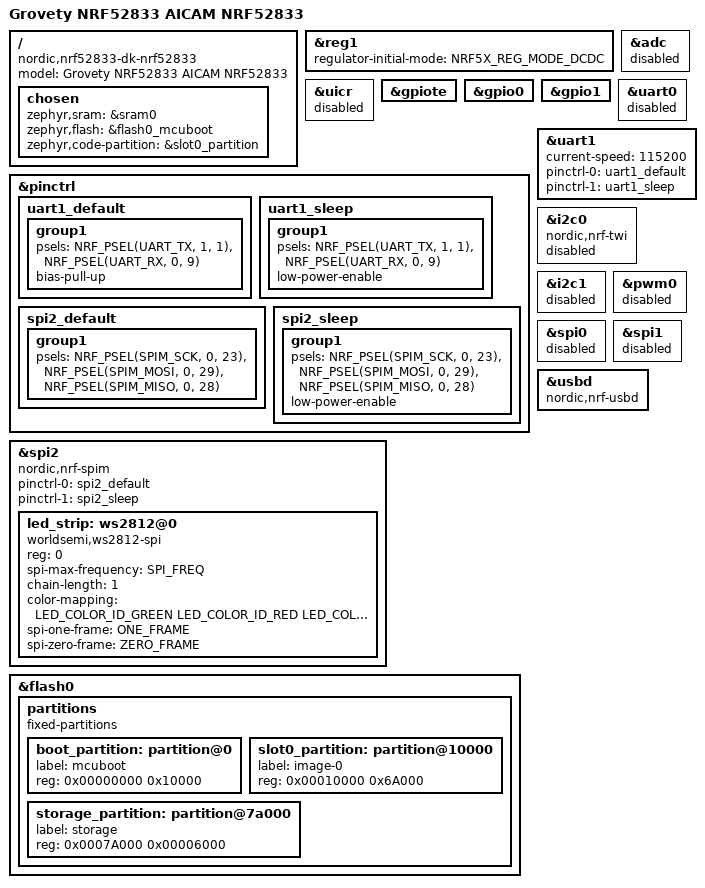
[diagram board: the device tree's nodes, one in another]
/*
 * Copyright (c) 2025 Grovety Inc
 *
 * SPDX-License-Identifier: Apache-2.0
 */

/dts-v1/;
#include <nordic/nrf52833_qiaa.dtsi>
#include <zephyr/dt-bindings/input/input-event-codes.h>

/ {
	model = "Grovety NRF52833 AICAM NRF52833";
	compatible = "nordic,nrf52833-dk-nrf52833";

	chosen {
		zephyr,sram = &sram0;
		zephyr,flash = &flash0_mcuboot;
		zephyr,code-partition = &slot0_partition;
	};
};

&reg1 {
	regulator-initial-mode = <NRF5X_REG_MODE_DCDC>;
};

&adc {
	status = "disabled";
};

&uicr {
	status = "disabled";
};

&gpiote {
	status = "okay";
};

&gpio0 {
	status = "okay";
};

&gpio1 {
	status = "okay";
};

&uart0 {
	status = "disabled";
};

&pinctrl {
	uart1_default: uart1_default {
		group1 {
			psels = <NRF_PSEL(UART_TX, 1, 1)>,
			        <NRF_PSEL(UART_RX, 0, 9)>;
		bias-pull-up;
	  };
	};
	uart1_sleep: uart1_sleep {
	  	group1 {
			psels = <NRF_PSEL(UART_TX, 1, 1)>,
			        <NRF_PSEL(UART_RX, 0, 9)>;
		low-power-enable;
	  	};
	};
};

&uart1 {
	status = "okay";
	current-speed = <115200>;
	pinctrl-0 = <&uart1_default>;
	pinctrl-1 = <&uart1_sleep>;
	pinctrl-names = "default", "sleep";
};

&i2c0 {
	compatible = "nordic,nrf-twi";
	status = "disabled";
};

&i2c1 {
	status = "disabled";
};

&pwm0 {
	status = "disabled";
};

&spi0 {
	status = "disabled";
};

&spi1 {
	status = "disabled";
};

&spi2 {
	status = "disabled";
};

/*flash0_default: &flash0 {
	partitions {
		compatible = "fixed-partitions";
		#address-cells = <1>;
		#size-cells = <1>;

		boot_partition: partition@0 {
			label = "mcuboot";
			reg = <0x00000000 0xC000>;
		};
		slot0_partition: partition@c000 {
			label = "image-0";
			reg = <0x0000C000 0x37000>;
		};
		slot1_partition: partition@43000 {
			label = "image-1";
			reg = <0x00043000 0x37000>;
		};
		storage_partition: partition@7a000 {
			label = "storage";
			reg = <0x0007A000 0x00006000>;
		};
	};
};*/

flash0_mcuboot: &flash0 {
	partitions {
		compatible = "fixed-partitions";
		#address-cells = <1>;
		#size-cells = <1>;

		boot_partition: partition@0 {
			label = "mcuboot";
			reg = <0x00000000 0x10000>;
		};
		slot0_partition: partition@10000 {
			label = "image-0";
			reg = <0x00010000 0x6A000>;
		};
		storage_partition: partition@7a000 {
			label = "storage";
			reg = <0x0007A000 0x00006000>;
		};
	};
};

zephyr_udc0: &usbd {
	compatible = "nordic,nrf-usbd";
	status = "okay";
};

&pinctrl {
	spi2_default: spi2_default {
		group1 {
			psels = <NRF_PSEL(SPIM_SCK, 0, 23)>, 		// dummy
					<NRF_PSEL(SPIM_MOSI, 0, 29)>, 		// stripe
					<NRF_PSEL(SPIM_MISO, 0, 28)>; 		// dummy

		};
	};
	spi2_sleep: spi2_sleep {
		group1 {
			psels = <NRF_PSEL(SPIM_SCK, 0, 23)>,
					<NRF_PSEL(SPIM_MOSI, 0, 29)>,
					<NRF_PSEL(SPIM_MISO, 0, 28)>;
			low-power-enable;
		};
	};
};

#include <zephyr/dt-bindings/led/led.h>

#define SPI_FREQ    4000000
#define ONE_FRAME   0x70
#define ZERO_FRAME  0x40

&spi2 {
	compatible = "nordic,nrf-spim";
	status = "okay";
	pinctrl-0 = <&spi2_default>;
	pinctrl-1 = <&spi2_sleep>;
	pinctrl-names = "default", "sleep";
	led_strip: ws2812@0 {
		compatible = "worldsemi,ws2812-spi";
		/* SPI */
		reg = <0>; /* ignored, but necessary for SPI bindings */
		spi-max-frequency = <SPI_FREQ>;
		/* WS2812 */
		chain-length = <1>; /* arbitrary; change at will */
		color-mapping = <LED_COLOR_ID_GREEN LED_COLOR_ID_RED LED_COLOR_ID_BLUE>;
		spi-one-frame = <ONE_FRAME>;
		spi-zero-frame = <ZERO_FRAME>;
	};
};
